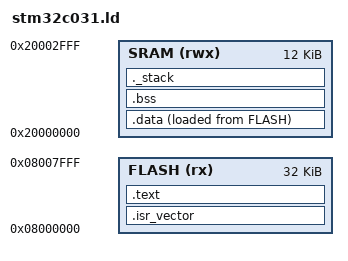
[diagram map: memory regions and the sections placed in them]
/* Linker script for STM32C031C6 (32KB Flash, 12KB SRAM) */
MEMORY
{
    FLASH (rx)  : ORIGIN = 0x08000000, LENGTH = 32K
    SRAM  (rwx) : ORIGIN = 0x20000000, LENGTH = 12K
}

/* Entry point */
ENTRY(Reset_Handler)

/* Initial stack pointer = top of SRAM */
_estack = ORIGIN(SRAM) + LENGTH(SRAM);

SECTIONS
{
    /* Vector table + code in Flash */
    .isr_vector :
    {
        . = ALIGN(4);
        KEEP(*(.isr_vector))
        . = ALIGN(4);
    } > FLASH

    .text :
    {
        . = ALIGN(4);
        *(.text)
        *(.text*)
        *(.init)
        *(.fini)
        *(.rodata)
        *(.rodata*)
        . = ALIGN(4);
        _etext = .;
    } > FLASH

    /* Initialized data: stored in Flash, copied to SRAM at startup */
    _sidata = LOADADDR(.data);
    .data :
    {
        . = ALIGN(4);
        _sdata = .;
        *(.data)
        *(.data*)
        . = ALIGN(4);
        _edata = .;
    } > SRAM AT > FLASH

    /* Zero-initialized data in SRAM */
    .bss :
    {
        . = ALIGN(4);
        _sbss = .;
        *(.bss)
        *(.bss*)
        *(COMMON)
        . = ALIGN(4);
        _ebss = .;
    } > SRAM

    /* Stack */
    ._stack :
    {
        . = ALIGN(8);
        _end = .;
        PROVIDE(end = .);
    } > SRAM
}
